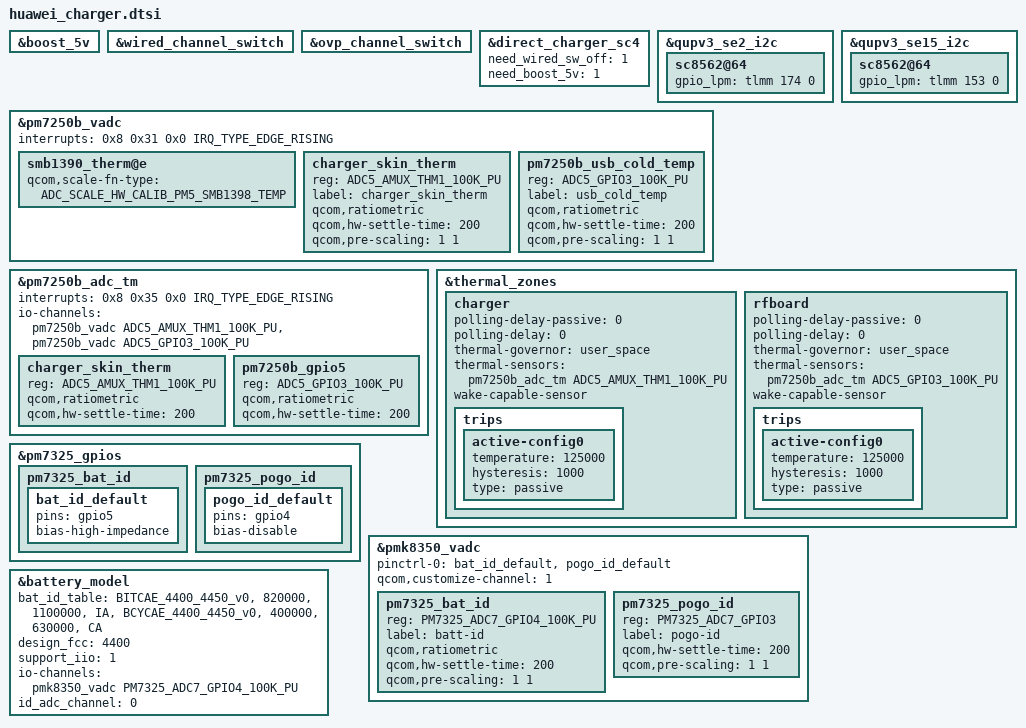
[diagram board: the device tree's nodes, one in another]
#include <dt-bindings/iio/qcom,spmi-vadc.h>
&boost_5v {
	status = "ok";
};

&wired_channel_switch {
	status = "ok";
};

&ovp_channel_switch {
	status = "ok";
};

&direct_charger_sc4 {
	need_wired_sw_off = <1>;
	need_boost_5v = <1>;
};

&qupv3_se2_i2c {
	sc8562@64{
		gpio_lpm = <&tlmm 174 0>;
		status = "ok";
	};
};

&qupv3_se15_i2c {
	sc8562@64{
		gpio_lpm = <&tlmm 153 0>;
		status = "ok";
	};
};

&pm7250b_vadc {
	interrupts = <0x8 0x31 0x0 IRQ_TYPE_EDGE_RISING>;

	smb1390_therm@e {
		qcom,scale-fn-type = <ADC_SCALE_HW_CALIB_PM5_SMB1398_TEMP>;
	};

	charger_skin_therm {
		reg = <ADC5_AMUX_THM1_100K_PU>;
		label = "charger_skin_therm";
		qcom,ratiometric;
		qcom,hw-settle-time = <200>;
		qcom,pre-scaling = <1 1>;
	};

	pm7250b_usb_cold_temp {
		reg = <ADC5_GPIO3_100K_PU>;
		label = "usb_cold_temp";
		qcom,ratiometric;
		qcom,hw-settle-time = <200>;
		qcom,pre-scaling = <1 1>;
	};
};

&pm7250b_adc_tm {
	interrupts = <0x8 0x35 0x0 IRQ_TYPE_EDGE_RISING>;

	io-channels = <&pm7250b_vadc ADC5_AMUX_THM1_100K_PU>,
             <&pm7250b_vadc ADC5_GPIO3_100K_PU>;

	charger_skin_therm {
		reg = <ADC5_AMUX_THM1_100K_PU>;
		qcom,ratiometric;
		qcom,hw-settle-time = <200>;
	};

	pm7250b_gpio5 {
		reg = <ADC5_GPIO3_100K_PU>;
		qcom,ratiometric;
		qcom,hw-settle-time = <200>;
	};
};

&thermal_zones {

	charger {
		polling-delay-passive = <0>;
		polling-delay = <0>;
		thermal-governor = "user_space";
		thermal-sensors = <&pm7250b_adc_tm ADC5_AMUX_THM1_100K_PU>;
		wake-capable-sensor;
		trips {
			active-config0 {
				temperature = <125000>;
				hysteresis = <1000>;
				type = "passive";
			};
		};
	};

	rfboard {
		polling-delay-passive = <0>;
		polling-delay = <0>;
		thermal-governor = "user_space";
		thermal-sensors = <&pm7250b_adc_tm ADC5_GPIO3_100K_PU>;
		wake-capable-sensor;
		trips {
			active-config0 {
				temperature = <125000>;
				hysteresis = <1000>;
				type = "passive";
			};
		};
	};
};

&pm7325_gpios {
	pm7325_bat_id {
		bat_id_default: bat_id_default {
		pins = "gpio5";
		bias-high-impedance;
		};
	};

	pm7325_pogo_id {
		pogo_id_default: pogo_id_default {
			pins = "gpio4";
			bias-disable;
		};
	};
};

&pmk8350_vadc {
	pinctrl-names = "default";
	pinctrl-0 = < &bat_id_default &pogo_id_default>;
	qcom,customize-channel = <1>;
	pm7325_bat_id {
		reg = < PM7325_ADC7_GPIO4_100K_PU>;
		label = "batt-id";
		qcom,ratiometric;
		qcom,hw-settle-time = <200>;
		qcom,pre-scaling = <1 1>;
	};

	pm7325_pogo_id {
		reg = <PM7325_ADC7_GPIO3>;
		label = "pogo-id";
		qcom,hw-settle-time = <200>;
		qcom,pre-scaling = <1 1>;
	};
};

&battery_model {
        bat_id_table =
                "BITCAE_4400_4450_v0", "820000", "1100000", "IA",
                "BCYCAE_4400_4450_v0", "400000", "630000", "CA";
        design_fcc = <4400>;
        support_iio = <1>;
        io-channels = <&pmk8350_vadc PM7325_ADC7_GPIO4_100K_PU>;
        io-channel-names = "batt-id";
        id_adc_channel = <0>; /* useless but necessary for Qcom, set 0 as default */
        status = "ok";
};

